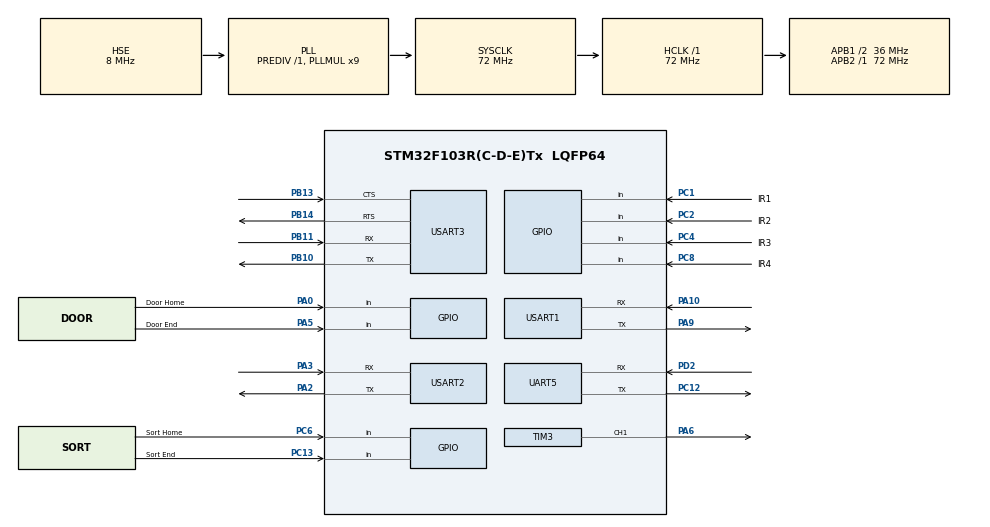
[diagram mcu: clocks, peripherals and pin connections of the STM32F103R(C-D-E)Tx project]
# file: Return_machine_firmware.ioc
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Dma.Request0=USART1_TX
Dma.Request1=USART1_RX
Dma.USART1_RX.1.Direction=DMA_PERIPH_TO_MEMORY
Dma.USART1_RX.1.Instance=DMA1_Channel5
Dma.USART1_RX.1.MemDataAlignment=DMA_MDATAALIGN_BYTE
Dma.USART1_RX.1.MemInc=DMA_MINC_ENABLE
Dma.USART1_RX.1.Mode=DMA_CIRCULAR
Dma.USART1_RX.1.PeriphDataAlignment=DMA_PDATAALIGN_BYTE
Dma.USART1_RX.1.PeriphInc=DMA_PINC_DISABLE
Dma.USART1_RX.1.Priority=DMA_PRIORITY_VERY_HIGH
Dma.USART1_TX.0.Direction=DMA_MEMORY_TO_PERIPH
Dma.USART1_TX.0.Instance=DMA1_Channel4
Dma.USART1_TX.0.MemDataAlignment=DMA_MDATAALIGN_BYTE
Dma.USART1_TX.0.MemInc=DMA_MINC_ENABLE
Dma.USART1_TX.0.Mode=DMA_CIRCULAR
Dma.USART1_TX.0.PeriphDataAlignment=DMA_PDATAALIGN_BYTE
Dma.USART1_TX.0.PeriphInc=DMA_PINC_DISABLE
Dma.USART1_TX.0.Priority=DMA_PRIORITY_HIGH
FREERTOS.Tasks01=SystemTask,40,512,StartSystemTask,Default,NULL,Dynamic,NULL,NULL;CommunicationTa,32,768,StartCommunicationTask,Default,NULL,Dynamic,NULL,NULL;SensorTask,24,512,StartSensorTask,Default,NULL,Dynamic,NULL,NULL;ActuatorTask,24,512,StartActuatorTask,Default,NULL,Dynamic,NULL,NULL
FREERTOS.configTOTAL_HEAP_SIZE=24576
Mcu.Family=STM32F1
Mcu.Name=STM32F103R(C-D-E)Tx
Mcu.Package=LQFP64
NVIC.DMA1_Channel4_IRQn=true\:5\:0\:false\:false\:true\:true\:false\:true\:true
NVIC.DMA1_Channel5_IRQn=true\:5\:0\:false\:false\:true\:true\:false\:true\:true
NVIC.PVD_IRQn=true\:7\:0\:true\:false\:true\:true\:true\:true\:true
NVIC.PriorityGroup=NVIC_PRIORITYGROUP_4
NVIC.TIM3_IRQn=true\:8\:0\:true\:false\:true\:true\:true\:true\:true
NVIC.UART5_IRQn=true\:6\:0\:true\:false\:true\:true\:true\:true\:true
NVIC.USART1_IRQn=true\:5\:0\:false\:false\:true\:true\:true\:true\:true
NVIC.USART2_IRQn=true\:6\:0\:true\:false\:true\:true\:true\:true\:true
NVIC.USART3_IRQn=true\:6\:0\:true\:false\:true\:true\:true\:true\:true
PA0-WKUP.GPIO_Label=Door Home
PA0-WKUP.Signal=GPIO_Input
PA10.Mode=Asynchronous
PA10.Signal=USART1_RX
PA2.Mode=Asynchronous
PA2.Signal=USART2_TX
PA3.Mode=Asynchronous
PA3.Signal=USART2_RX
PA5.GPIO_Label=Door End
PA5.Signal=GPIO_Input
PA6.Signal=S_TIM3_CH1
PA9.Mode=Asynchronous
PA9.Signal=USART1_TX
PB10.Mode=Asynchronous
PB10.Signal=USART3_TX
PB11.Mode=Asynchronous
PB11.Signal=USART3_RX
PB13.Mode=CTS_RTS
PB13.Signal=USART3_CTS
PB14.Mode=CTS_RTS
PB14.Signal=USART3_RTS
PC1.GPIO_Label=IR1
PC1.Signal=GPIO_Input
PC12.Mode=Asynchronous
PC12.Signal=UART5_TX
PC13-TAMPER-RTC.GPIO_Label=Sort End
PC13-TAMPER-RTC.Signal=GPIO_Input
PC2.GPIO_Label=IR2
PC2.Signal=GPIO_Input
PC4.GPIO_Label=IR3
PC4.Signal=GPIO_Input
PC6.GPIO_Label=Sort Home
PC6.Signal=GPIO_Input
PC8.GPIO_Label=IR4
PC8.Signal=GPIO_Input
PD0-OSC_IN.Mode=HSE-External-Oscillator
PD0-OSC_IN.Signal=RCC_OSC_IN
PD1-OSC_OUT.Mode=HSE-External-Oscillator
PD1-OSC_OUT.Signal=RCC_OSC_OUT
PD2.Mode=Asynchronous
PD2.Signal=UART5_RX
ProjectManager.HeapSize=0x200
ProjectManager.StackSize=0x400
ProjectManager.TargetToolchain=STM32CubeIDE
RCC.AHBFreq_Value=72000000
RCC.APB1CLKDivider=RCC_HCLK_DIV2
RCC.APB1Freq_Value=36000000
RCC.APB1TimFreq_Value=72000000
RCC.APB2Freq_Value=72000000
RCC.APB2TimFreq_Value=72000000
RCC.HCLKFreq_Value=72000000
RCC.PLLMUL=RCC_PLL_MUL9
RCC.PLLSourceVirtual=RCC_PLLSOURCE_HSE
RCC.SYSCLKFreq_VALUE=72000000
RCC.SYSCLKSource=RCC_SYSCLKSOURCE_PLLCLK
RCC.USBFreq_Value=72000000
SH.S_TIM3_CH1.0=TIM3_CH1,PWM Generation1 CH1
TIM3.AutoReloadPreload=TIM_AUTORELOAD_PRELOAD_ENABLE
TIM3.Channel-PWM\ Generation1\ CH1=TIM_CHANNEL_1
TIM3.Period=999
TIM3.Prescaler=71
UART5.VirtualMode=Asynchronous
USART1.VirtualMode=VM_ASYNC
USART2.VirtualMode=VM_ASYNC
USART3.VirtualMode=VM_ASYNC
VP_FREERTOS_VS_CMSIS_V2.Mode=CMSIS_V2
VP_SYS_VS_ND.Mode=No_Debug
VP_TIM3_VS_ClockSourceINT.Mode=Internal
board=custom

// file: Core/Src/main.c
/* USER CODE BEGIN Header */
/**
  ******************************************************************************
  * @file           : main.c
  * @brief          : Main program body
  ******************************************************************************
  * @attention
  *
  * Copyright (c) 2026 STMicroelectronics.
  * All rights reserved.
  *
  * This software is licensed under terms that can be found in the LICENSE file
  * in the root directory of this software component.
  * If no LICENSE file comes with this software, it is provided AS-IS.
  *
  ******************************************************************************
  */
/* USER CODE END Header */
#include "main.h"
#include "cmsis_os.h"

/* USER CODE BEGIN Includes */
#include "../App/app_init.h"
#include "communication_service.h"
/* USER CODE END Includes */

TIM_HandleTypeDef htim3;

UART_HandleTypeDef huart5;
UART_HandleTypeDef huart1;
UART_HandleTypeDef huart2;
UART_HandleTypeDef huart3;
DMA_HandleTypeDef hdma_usart1_tx;
DMA_HandleTypeDef hdma_usart1_rx;

/* Definitions for SystemTask */
osThreadId_t SystemTaskHandle;
const osThreadAttr_t SystemTask_attributes = {
  .name = "SystemTask",
  .stack_size = 512 * 4,
  .priority = (osPriority_t) osPriorityHigh,
};
/* Definitions for CommunicationTa */
osThreadId_t CommunicationTaHandle;
const osThreadAttr_t CommunicationTa_attributes = {
  .name = "CommunicationTa",
  .stack_size = 768 * 4,
  .priority = (osPriority_t) osPriorityAboveNormal,
};
/* Definitions for SensorTask */
osThreadId_t SensorTaskHandle;
const osThreadAttr_t SensorTask_attributes = {
  .name = "SensorTask",
  .stack_size = 512 * 4,
  .priority = (osPriority_t) osPriorityNormal,
};
/* Definitions for ActuatorTask */
osThreadId_t ActuatorTaskHandle;
const osThreadAttr_t ActuatorTask_attributes = {
  .name = "ActuatorTask",
  .stack_size = 512 * 4,
  .priority = (osPriority_t) osPriorityNormal,
};

void SystemClock_Config(void);
static void MX_GPIO_Init(void);
static void MX_DMA_Init(void);
static void MX_TIM3_Init(void);
static void MX_UART5_Init(void);
static void MX_USART1_UART_Init(void);
static void MX_USART2_UART_Init(void);
static void MX_USART3_UART_Init(void);
void StartSystemTask(void *argument);
void StartCommunicationTask(void *argument);
void StartSensorTask(void *argument);
void StartActuatorTask(void *argument);

int main(void)
{

  /* MCU Configuration--------------------------------------------------------*/

  /* Reset of all peripherals, Initializes the Flash interface and the Systick. */
  HAL_Init();

  /* Configure the system clock */
  SystemClock_Config();

  /* Initialize all configured peripherals */
  MX_GPIO_Init();
  MX_DMA_Init();
  MX_TIM3_Init();
  MX_UART5_Init();
  MX_USART1_UART_Init();
  MX_USART2_UART_Init();
  MX_USART3_UART_Init();
  /* USER CODE BEGIN 2 */
  App_Init();
  /* USER CODE END 2 */

  /* Init scheduler */
  osKernelInitialize();

  /* Create the thread(s) */
  /* creation of SystemTask */
  SystemTaskHandle = osThreadNew(StartSystemTask, NULL, &SystemTask_attributes);

  /* creation of CommunicationTa */
  CommunicationTaHandle = osThreadNew(StartCommunicationTask, NULL, &CommunicationTa_attributes);

  /* creation of SensorTask */
  SensorTaskHandle = osThreadNew(StartSensorTask, NULL, &SensorTask_attributes);

  /* creation of ActuatorTask */
  ActuatorTaskHandle = osThreadNew(StartActuatorTask, NULL, &ActuatorTask_attributes);

  /* Start scheduler */
  osKernelStart();

  /* We should never get here as control is now taken by the scheduler */

  /* Infinite loop */
  while (1)
  {

  }
}

void SystemClock_Config(void)
{
  RCC_OscInitTypeDef RCC_OscInitStruct = {0};
  RCC_ClkInitTypeDef RCC_ClkInitStruct = {0};

  /** Initializes the RCC Oscillators according to the specified parameters
  * in the RCC_OscInitTypeDef structure.
  */
  RCC_OscInitStruct.OscillatorType = RCC_OSCILLATORTYPE_HSE;
  RCC_OscInitStruct.HSEState = RCC_HSE_ON;
  RCC_OscInitStruct.HSEPredivValue = RCC_HSE_PREDIV_DIV1;
  RCC_OscInitStruct.HSIState = RCC_HSI_ON;
  RCC_OscInitStruct.PLL.PLLState = RCC_PLL_ON;
  RCC_OscInitStruct.PLL.PLLSource = RCC_PLLSOURCE_HSE;
  RCC_OscInitStruct.PLL.PLLMUL = RCC_PLL_MUL9;
  if (HAL_RCC_OscConfig(&RCC_OscInitStruct) != HAL_OK)
  {
    Error_Handler();
  }

  /** Initializes the CPU, AHB and APB buses clocks
  */
  RCC_ClkInitStruct.ClockType = RCC_CLOCKTYPE_HCLK|RCC_CLOCKTYPE_SYSCLK
                              |RCC_CLOCKTYPE_PCLK1|RCC_CLOCKTYPE_PCLK2;
  RCC_ClkInitStruct.SYSCLKSource = RCC_SYSCLKSOURCE_PLLCLK;
  RCC_ClkInitStruct.AHBCLKDivider = RCC_SYSCLK_DIV1;
  RCC_ClkInitStruct.APB1CLKDivider = RCC_HCLK_DIV2;
  RCC_ClkInitStruct.APB2CLKDivider = RCC_HCLK_DIV1;

  if (HAL_RCC_ClockConfig(&RCC_ClkInitStruct, FLASH_LATENCY_2) != HAL_OK)
  {
    Error_Handler();
  }
}

static void MX_TIM3_Init(void)
{

  TIM_ClockConfigTypeDef sClockSourceConfig = {0};
  TIM_MasterConfigTypeDef sMasterConfig = {0};
  TIM_OC_InitTypeDef sConfigOC = {0};

  htim3.Instance = TIM3;
  htim3.Init.Prescaler = 71;
  htim3.Init.CounterMode = TIM_COUNTERMODE_UP;
  htim3.Init.Period = 999;
  htim3.Init.ClockDivision = TIM_CLOCKDIVISION_DIV1;
  htim3.Init.AutoReloadPreload = TIM_AUTORELOAD_PRELOAD_ENABLE;
  if (HAL_TIM_Base_Init(&htim3) != HAL_OK)
  {
    Error_Handler();
  }
  sClockSourceConfig.ClockSource = TIM_CLOCKSOURCE_INTERNAL;
  if (HAL_TIM_ConfigClockSource(&htim3, &sClockSourceConfig) != HAL_OK)
  {
    Error_Handler();
  }
  if (HAL_TIM_PWM_Init(&htim3) != HAL_OK)
  {
    Error_Handler();
  }
  sMasterConfig.MasterOutputTrigger = TIM_TRGO_RESET;
  sMasterConfig.MasterSlaveMode = TIM_MASTERSLAVEMODE_DISABLE;
  if (HAL_TIMEx_MasterConfigSynchronization(&htim3, &sMasterConfig) != HAL_OK)
  {
    Error_Handler();
  }
  sConfigOC.OCMode = TIM_OCMODE_PWM1;
  sConfigOC.Pulse = 0;
  sConfigOC.OCPolarity = TIM_OCPOLARITY_HIGH;
  sConfigOC.OCFastMode = TIM_OCFAST_DISABLE;
  if (HAL_TIM_PWM_ConfigChannel(&htim3, &sConfigOC, TIM_CHANNEL_1) != HAL_OK)
  {
    Error_Handler();
  }
  HAL_TIM_MspPostInit(&htim3);

}

static void MX_UART5_Init(void)
{

  huart5.Instance = UART5;
  huart5.Init.BaudRate = 115200;
  huart5.Init.WordLength = UART_WORDLENGTH_8B;
  huart5.Init.StopBits = UART_STOPBITS_1;
  huart5.Init.Parity = UART_PARITY_NONE;
  huart5.Init.Mode = UART_MODE_TX_RX;
  huart5.Init.HwFlowCtl = UART_HWCONTROL_NONE;
  huart5.Init.OverSampling = UART_OVERSAMPLING_16;
  if (HAL_UART_Init(&huart5) != HAL_OK)
  {
    Error_Handler();
  }

}

static void MX_USART1_UART_Init(void)
{

  huart1.Instance = USART1;
  huart1.Init.BaudRate = 115200;
  huart1.Init.WordLength = UART_WORDLENGTH_8B;
  huart1.Init.StopBits = UART_STOPBITS_1;
  huart1.Init.Parity = UART_PARITY_NONE;
  huart1.Init.Mode = UART_MODE_TX_RX;
  huart1.Init.HwFlowCtl = UART_HWCONTROL_NONE;
  huart1.Init.OverSampling = UART_OVERSAMPLING_16;
  if (HAL_UART_Init(&huart1) != HAL_OK)
  {
    Error_Handler();
  }

}

static void MX_USART2_UART_Init(void)
{

  huart2.Instance = USART2;
  huart2.Init.BaudRate = 115200;
  huart2.Init.WordLength = UART_WORDLENGTH_8B;
  huart2.Init.StopBits = UART_STOPBITS_1;
  huart2.Init.Parity = UART_PARITY_NONE;
  huart2.Init.Mode = UART_MODE_TX_RX;
  huart2.Init.HwFlowCtl = UART_HWCONTROL_NONE;
  huart2.Init.OverSampling = UART_OVERSAMPLING_16;
  if (HAL_UART_Init(&huart2) != HAL_OK)
  {
    Error_Handler();
  }

}

static void MX_USART3_UART_Init(void)
{

  huart3.Instance = USART3;
  huart3.Init.BaudRate = 115200;
  huart3.Init.WordLength = UART_WORDLENGTH_8B;
  huart3.Init.StopBits = UART_STOPBITS_1;
  huart3.Init.Parity = UART_PARITY_NONE;
  huart3.Init.Mode = UART_MODE_TX_RX;
  huart3.Init.HwFlowCtl = UART_HWCONTROL_RTS_CTS;
  huart3.Init.OverSampling = UART_OVERSAMPLING_16;
  if (HAL_UART_Init(&huart3) != HAL_OK)
  {
    Error_Handler();
  }

}

static void MX_DMA_Init(void)
{

  /* DMA controller clock enable */
  __HAL_RCC_DMA1_CLK_ENABLE();

  /* DMA interrupt init */
  /* DMA1_Channel4_IRQn interrupt configuration */
  HAL_NVIC_SetPriority(DMA1_Channel4_IRQn, 5, 0);
  HAL_NVIC_EnableIRQ(DMA1_Channel4_IRQn);
  /* DMA1_Channel5_IRQn interrupt configuration */
  HAL_NVIC_SetPriority(DMA1_Channel5_IRQn, 5, 0);
  HAL_NVIC_EnableIRQ(DMA1_Channel5_IRQn);

}

static void MX_GPIO_Init(void)
{
  GPIO_InitTypeDef GPIO_InitStruct = {0};

  /* GPIO Ports Clock Enable */
  __HAL_RCC_GPIOC_CLK_ENABLE();
  __HAL_RCC_GPIOD_CLK_ENABLE();
  __HAL_RCC_GPIOA_CLK_ENABLE();
  __HAL_RCC_GPIOB_CLK_ENABLE();

  /*Configure GPIO pins : Sort_End_Pin IR1_Pin IR2_Pin IR3_Pin
                           Sort_Home_Pin IR4_Pin */
  GPIO_InitStruct.Pin = Sort_End_Pin|IR1_Pin|IR2_Pin|IR3_Pin
                          |Sort_Home_Pin|IR4_Pin;
  GPIO_InitStruct.Mode = GPIO_MODE_INPUT;
  GPIO_InitStruct.Pull = GPIO_NOPULL;
  HAL_GPIO_Init(GPIOC, &GPIO_InitStruct);

  /*Configure GPIO pins : Door_Home_Pin Door_End_Pin */
  GPIO_InitStruct.Pin = Door_Home_Pin|Door_End_Pin;
  GPIO_InitStruct.Mode = GPIO_MODE_INPUT;
  GPIO_InitStruct.Pull = GPIO_NOPULL;
  HAL_GPIO_Init(GPIOA, &GPIO_InitStruct);

}

void StartSystemTask(void *argument)
{
  /* USER CODE BEGIN 5 */
  /* Infinite loop */
  for(;;)
  {
    #ifdef DEBUG
    // Profile stack watermark high water mark
    uint32_t watermark = uxTaskGetStackHighWaterMark(NULL);
    (void)watermark;
    #endif
    osDelay(100);
  }
  /* USER CODE END 5 */
}

void StartCommunicationTask(void *argument)
{
  /* USER CODE BEGIN StartCommunicationTask */
  CommunicationService_Init();
  /* Infinite loop */
  for(;;)
  {
    CommunicationService_ProcessRx();
    CommunicationService_ProcessQueue();
    osDelay(1);
  }
  /* USER CODE END StartCommunicationTask */
}

void StartSensorTask(void *argument)
{
  for(;;)
  {
    osDelay(1);
  }
}

void StartActuatorTask(void *argument)
{
  for(;;)
  {
    osDelay(1);
  }
}

void Error_Handler(void)
{
  __disable_irq();
  while (1)
  {
  }
}
